# CY8C4xxx register map
File version: 0.1
Registers are 8-bit, read-write, no defined reset value unless marked. A register's access mark holds for its fields unless they carry their own. Offsets are from the block's base; [hi:lo] are bit positions; 'fields as' and 'values as' point back to an identical list.

## CPUSS — CPU Subsystem
Base 0x40000000
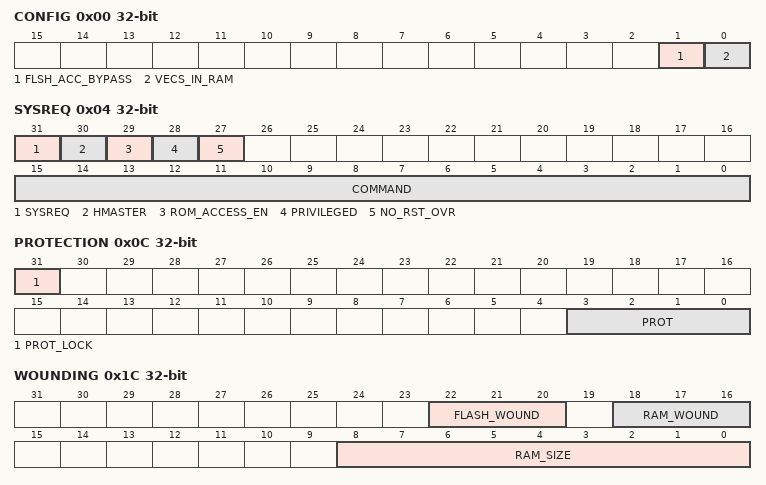
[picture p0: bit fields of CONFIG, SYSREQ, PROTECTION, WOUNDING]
0x00 CONFIG 32-bit — CPU Subsystem Configuration
  [1] FLSH_ACC_BYPASS — 0: Normal operation?1: Flash Accellerator in bypass mode, functions as single 64b line buffer.
  [0] VECS_IN_RAM — 0: Vector Table is located at 0000_0000 in Flash?1: Vector Table is located at 2000_0000 in RAM?Note that vectors for RESET and FAULT are always fetched from ROM. Value in Flash/RAM is ignored for these vectores.
0x04 SYSREQ 32-bit — System Request Register
  [31] SYSREQ — Firmware/ATE writes 1 to request a system call. This will lead to an immediate NMI (non maskable interrupt). System call implementation will write 0 after servicing the request.
  [30] HMASTER ro — 0: Request was made by Cortex-M0 CPU firmware?1: Request was made by external debugger/ATE probe?Note that any writes to this register while SYSREQ=1 will not change the value of HMASTER (such that the origin of a request can continue to be observed).
  [29] ROM_ACCESS_EN ro — Indicates that access to ROM is currently enabled. This bit is used for debug purposes only.
  [28] PRIVILEGED — Indicates whether the system is in privileged or user mode. This bit can only be set from ROM code. Any write to this register that is not originating from ROM will result in clearing this bit.
  [27] NO_RST_OVR — Disable Reset Vector fetch relocation:?0: CPU requests to locations 0000_0000 - 0000_0007 are redirected to SROM?1: CPU requests to locations 0000_0000 - 0000_0007 are made to flash.?Note that this bit defaults to 0 on reset, ensuring actual reset vector fetches are always made to ROM Flash DFT routines may set this bit to '1' to enable uninhibited read-back of programmed data in the first flash page.
  [15:0] COMMAND — Opcode of the system call being requested.
0x08 SYSARG 32-bit — System Request Argument Register
  [31:0] ARG32 — Argument to System Call specified in SYSREQ. Semantics of argument depends on system call made. Typically a pointer to a parameter block.
0x0C PROTECTION 32-bit
  [31] PROT_LOCK write-once — Setting this field will block (ignore) any further writes to the PROT field in this register. Once set, this field cannot be cleared.
  [3:0] PROT — Current protection mode - this field is available as a global signal everywhere in the system. Writes to this field are ignored when PROT_LOCK=1.
    0=VIRGIN; 1=OPEN; 2=PROTECTED; 4=KILL; 8=BOOT
0x10 PRIV_ROM 32-bit — Privileged Limit Register
  [7:0] ROM_LIMIT — Indicates the limit where the privileged area of ROM starts in increments of 256B.?0: Entire ROM is Privileged?1: First 256B are UserMode accessiable?...?Any number larger than the size of the ROM indicates that the entire ROM is user mode accessible.
0x14 PRIV_RAM 32-bit — Privileged Limit Register
  [8:0] RAM_LIMIT — Indicates the limit where the privileged area of SRAM starts in increments of 256B.?0: Entire SRAM is Privileged?1: First 256B are UserMode accessiable?...?Any number larger than the size of the RAM indicates that the entire ROM is user mode accessible.
0x18 PRIV_FLASH 32-bit — Privileged Limit Register
  [10:0] FLASH_LIMIT — Indicates the limit where the privileged area of FLASH starts in increments of 256B.?0: Entire FLASH is Privileged?1: First 256B are UserMode accessiable?...?Any number larger than the size of the FLASH indicates that the entire Flash is user mode accessible. Note that SuperVisory rows are always Privileged.?If FLASH_LIMIT defines a non-empty privileged area, the boot ROM will assume that a system call table exists at the beginning of the Flash privileged area and use it for all SystemCalls made using CPUSS_SYSREQ.?Note that marking the entire flash as Privileged will generally not work, since all system calls return to User mode before returning (and they would not be able to return to anything in Flash if it was entirely Privileged).
0x1C WOUNDING 32-bit — Wounding Control Register
  [22:20] FLASH_WOUND write-once — Indicates the amount of accessible Flash in this part. The value in this field is effectively write-once (it is only possible to set bits, not clear them). The remainder portion of RAM is not accessible and will return bus error when accessed (HRESP=1).
    0=FULL; 1=DIV_BY_2; 2=DIV_BY_4; 3=DIV_BY_8; 4=DIV_BY_16; 5=DIV_BY_32; 6=DIV_BY_64; 7=DIV_BY_128
  [18:16] RAM_WOUND write-once — Indicates the amount of accessible RAM in this part. The value in this field is effectively write-once (it is only possible to set bits, not clear them). The remainder portion of RAM is not accessible and will return bus error when accessed (HRESP=1).
    values as FLASH_WOUND
  [8:0] RAM_SIZE ro — Indicates size of RAM in this device in units of 256B (0: 0B, 1: 256B, 2: 512B ...)
0x20 INTR_SELECT 32-bit — Interrupt Multiplexer Select Register
  [31:0] SELECT32 — When bit<N> is set, NVIC IRQ<N> is connected to DSI. When cleared it is connected to its fixed function role as defined in SAS/PAS.
